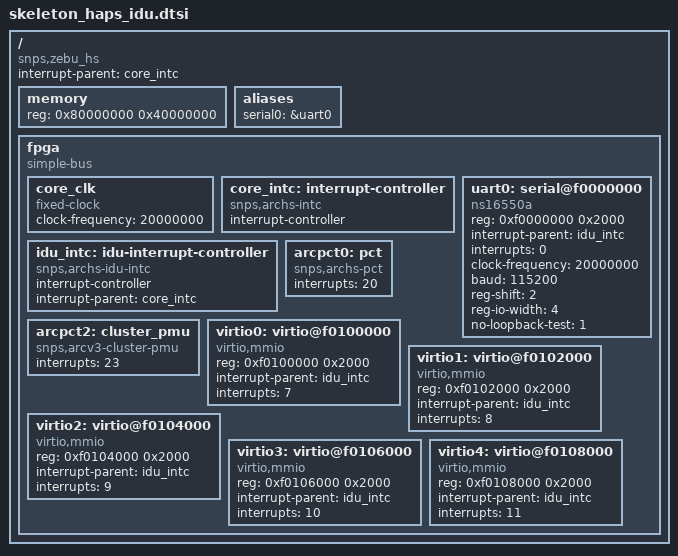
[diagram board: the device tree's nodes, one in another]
// SPDX-License-Identifier: GPL-2.0-only
/*
 * Copyright (C) 2023 Synopsys, Inc. (www.synopsys.com)
 */

/ {
	compatible = "snps,zebu_hs";
	#address-cells = <1>;
	#size-cells = <1>;
	interrupt-parent = <&core_intc>;

	memory {
		device_type = "memory";
		reg = <0x80000000 0x40000000>;	/* 1GB */
	};

	aliases {
		serial0 = &uart0;
	};

	fpga {
		compatible = "simple-bus";
		#address-cells = <1>;
		#size-cells = <1>;

		/* child and parent address space 1:1 mapped */
		ranges;

		core_clk: core_clk {
			#clock-cells = <0>;
			compatible = "fixed-clock";
			clock-frequency = <20000000>;	/* 20 MHZ */
		};

		core_intc: interrupt-controller {
			compatible = "snps,archs-intc";
			interrupt-controller;
			#interrupt-cells = <1>;
		};

		idu_intc: idu-interrupt-controller {
			compatible = "snps,archs-idu-intc";
			interrupt-controller;
			interrupt-parent = <&core_intc>;
			#interrupt-cells = <1>;
		};

		uart0: serial@f0000000 {
			compatible = "ns16550a";
			reg = <0xf0000000 0x2000>;
			interrupt-parent = <&idu_intc>;
			interrupts = <0>;
			clock-frequency = <20000000>;
			baud = <115200>;
			reg-shift = <2>;
			reg-io-width = <4>;
			no-loopback-test = <1>;
		};

		arcpct0: pct {
			compatible = "snps,archs-pct";
			#interrupt-cells = <1>;
			interrupts = <20>;
		};

		arcpct2: cluster_pmu {
			compatible = "snps,arcv3-cluster-pmu";
			#interrupt-cells = <1>;
			interrupts = <23>;
		};

		virtio0: virtio@f0100000 {
			compatible = "virtio,mmio";
			reg = <0xf0100000 0x2000>;
			interrupt-parent = <&idu_intc>;
			interrupts = <7>;
		};

		virtio1: virtio@f0102000 {
			compatible = "virtio,mmio";
			reg = <0xf0102000 0x2000>;
			interrupt-parent = <&idu_intc>;
			interrupts = <8>;
		};

		virtio2: virtio@f0104000 {
			compatible = "virtio,mmio";
			reg = <0xf0104000 0x2000>;
			interrupt-parent = <&idu_intc>;
			interrupts = <9>;
		};

		virtio3: virtio@f0106000 {
			compatible = "virtio,mmio";
			reg = <0xf0106000 0x2000>;
			interrupt-parent = <&idu_intc>;
			interrupts = <10>;
		};

		virtio4: virtio@f0108000 {
			compatible = "virtio,mmio";
			reg = <0xf0108000 0x2000>;
			interrupt-parent = <&idu_intc>;
			interrupts = <11>;
		};
	};
};
